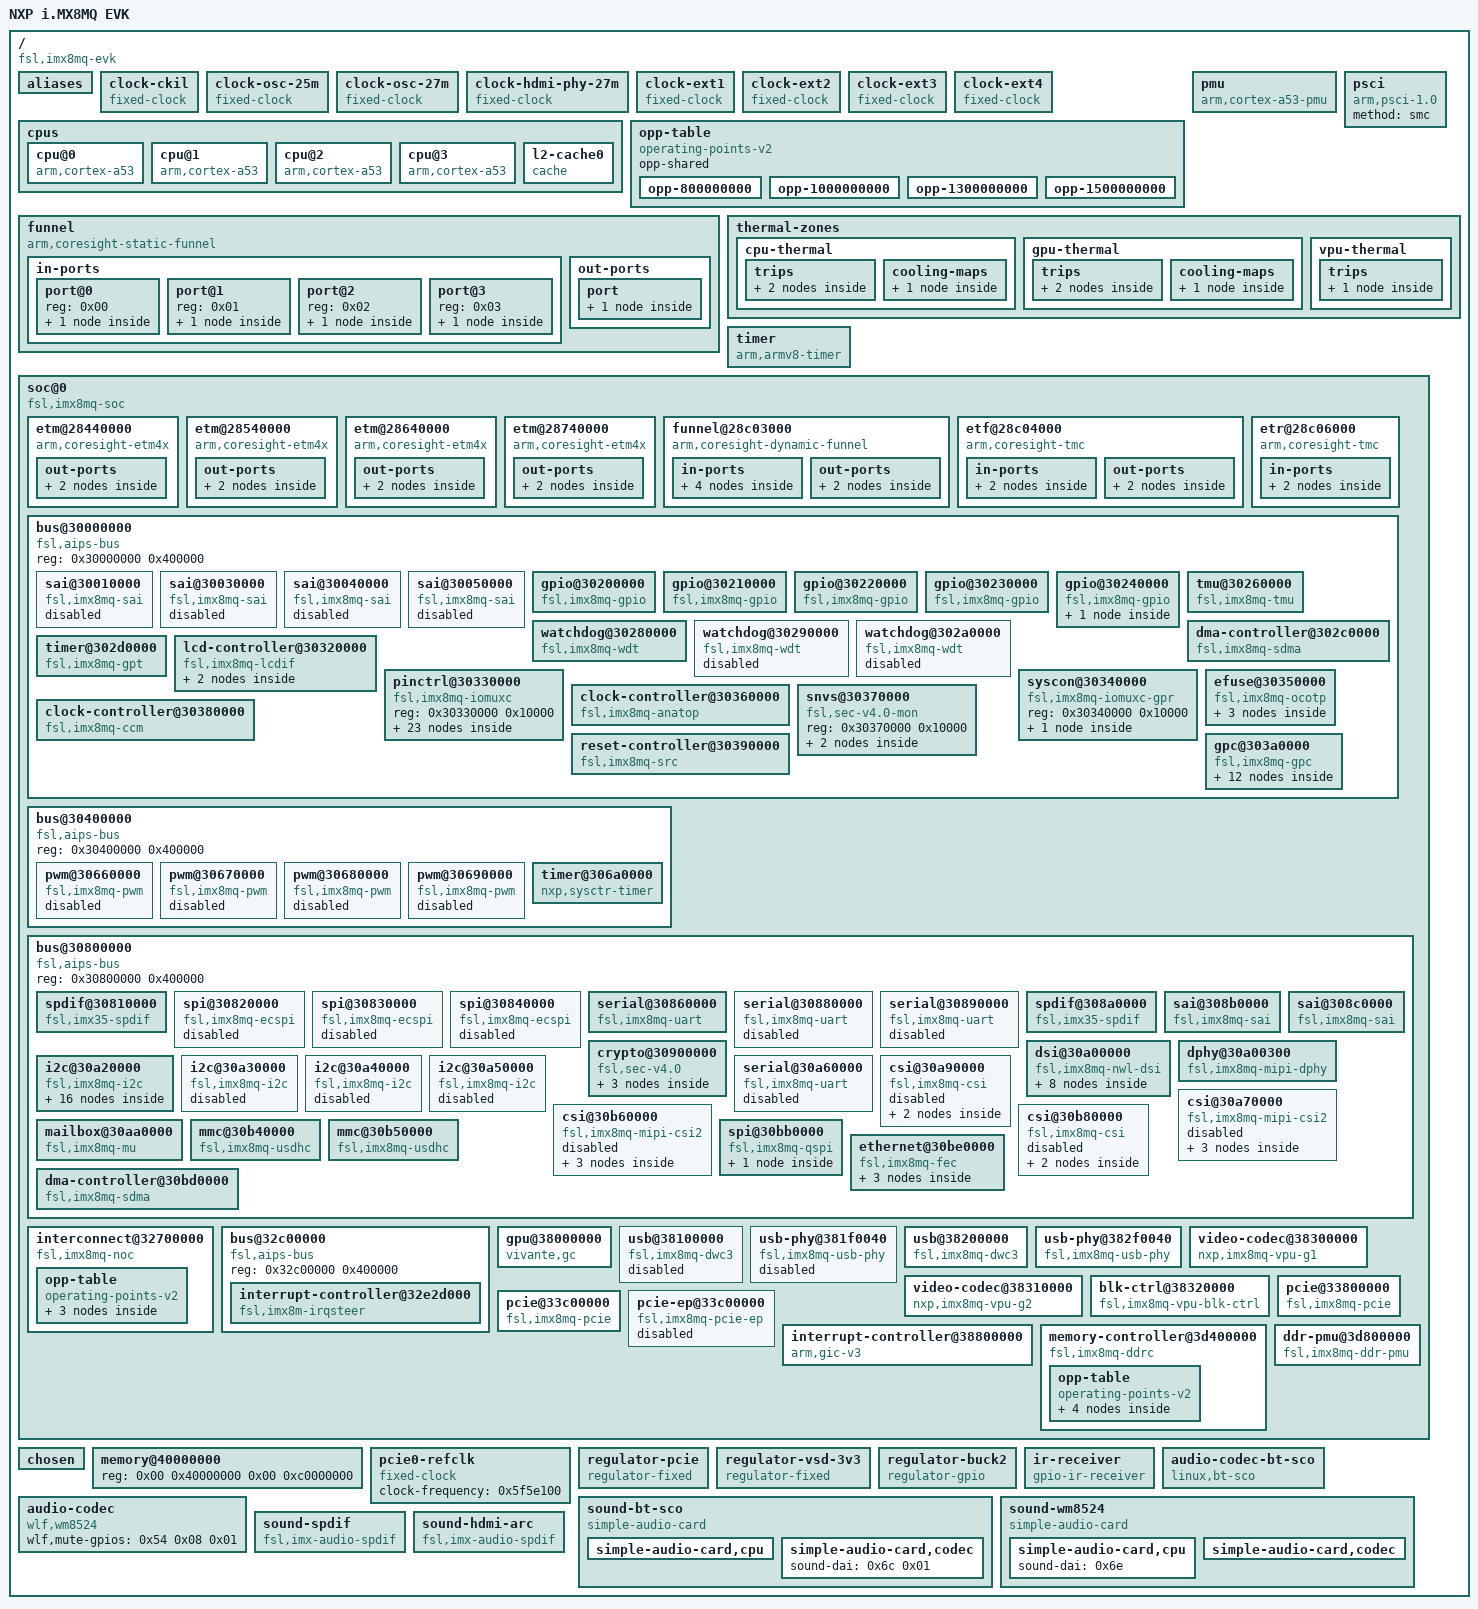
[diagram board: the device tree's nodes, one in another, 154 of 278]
/*
 * Copyright Linux Kernel Team
 *
 * SPDX-License-Identifier: GPL-2.0-only
 *
 * This file is derived from an intermediate build stage of the
 * Linux kernel. The licenses of all input files to this process
 * are compatible with GPL-2.0-only.
 */
/dts-v1/;

/ {
	interrupt-parent = <0x01>;
	#address-cells = <0x02>;
	#size-cells = <0x02>;
	model = "NXP i.MX8MQ EVK";
	compatible = "fsl,imx8mq-evk", "fsl,imx8mq";

	aliases {
		ethernet0 = "/soc@0/bus@30800000/ethernet@30be0000";
		gpio0 = "/soc@0/bus@30000000/gpio@30200000";
		gpio1 = "/soc@0/bus@30000000/gpio@30210000";
		gpio2 = "/soc@0/bus@30000000/gpio@30220000";
		gpio3 = "/soc@0/bus@30000000/gpio@30230000";
		gpio4 = "/soc@0/bus@30000000/gpio@30240000";
		i2c0 = "/soc@0/bus@30800000/i2c@30a20000";
		i2c1 = "/soc@0/bus@30800000/i2c@30a30000";
		i2c2 = "/soc@0/bus@30800000/i2c@30a40000";
		i2c3 = "/soc@0/bus@30800000/i2c@30a50000";
		mmc0 = "/soc@0/bus@30800000/mmc@30b40000";
		mmc1 = "/soc@0/bus@30800000/mmc@30b50000";
		serial0 = "/soc@0/bus@30800000/serial@30860000";
		serial1 = "/soc@0/bus@30800000/serial@30890000";
		serial2 = "/soc@0/bus@30800000/serial@30880000";
		serial3 = "/soc@0/bus@30800000/serial@30a60000";
		spi0 = "/soc@0/bus@30800000/spi@30820000";
		spi1 = "/soc@0/bus@30800000/spi@30830000";
		spi2 = "/soc@0/bus@30800000/spi@30840000";
	};

	clock-ckil {
		compatible = "fixed-clock";
		#clock-cells = <0x00>;
		clock-frequency = <0x8000>;
		clock-output-names = "ckil";
		phandle = <0x26>;
	};

	clock-osc-25m {
		compatible = "fixed-clock";
		#clock-cells = <0x00>;
		clock-frequency = <0x17d7840>;
		clock-output-names = "osc_25m";
		phandle = <0x27>;
	};

	clock-osc-27m {
		compatible = "fixed-clock";
		#clock-cells = <0x00>;
		clock-frequency = <0x19bfcc0>;
		clock-output-names = "osc_27m";
		phandle = <0x28>;
	};

	clock-hdmi-phy-27m {
		compatible = "fixed-clock";
		#clock-cells = <0x00>;
		clock-frequency = <0x19bfcc0>;
		clock-output-names = "hdmi_phy_27m";
	};

	clock-ext1 {
		compatible = "fixed-clock";
		#clock-cells = <0x00>;
		clock-frequency = <0x7ed6b40>;
		clock-output-names = "clk_ext1";
		phandle = <0x29>;
	};

	clock-ext2 {
		compatible = "fixed-clock";
		#clock-cells = <0x00>;
		clock-frequency = <0x7ed6b40>;
		clock-output-names = "clk_ext2";
		phandle = <0x2a>;
	};

	clock-ext3 {
		compatible = "fixed-clock";
		#clock-cells = <0x00>;
		clock-frequency = <0x7ed6b40>;
		clock-output-names = "clk_ext3";
		phandle = <0x2b>;
	};

	clock-ext4 {
		compatible = "fixed-clock";
		#clock-cells = <0x00>;
		clock-frequency = <0x7ed6b40>;
		clock-output-names = "clk_ext4";
		phandle = <0x2c>;
	};

	cpus {
		#address-cells = <0x01>;
		#size-cells = <0x00>;

		cpu@0 {
			device_type = "cpu";
			compatible = "arm,cortex-a53";
			reg = <0x00>;
			clock-latency = <0xee6c>;
			clocks = <0x02 0x102>;
			enable-method = "psci";
			i-cache-size = <0x8000>;
			i-cache-line-size = <0x40>;
			i-cache-sets = <0x100>;
			d-cache-size = <0x8000>;
			d-cache-line-size = <0x40>;
			d-cache-sets = <0x80>;
			next-level-cache = <0x03>;
			operating-points-v2 = <0x04>;
			#cooling-cells = <0x02>;
			nvmem-cells = <0x05>;
			nvmem-cell-names = "speed_grade";
			cpu-supply = <0x06>;
			phandle = <0x0f>;
		};

		cpu@1 {
			device_type = "cpu";
			compatible = "arm,cortex-a53";
			reg = <0x01>;
			clock-latency = <0xee6c>;
			clocks = <0x02 0x102>;
			enable-method = "psci";
			i-cache-size = <0x8000>;
			i-cache-line-size = <0x40>;
			i-cache-sets = <0x100>;
			d-cache-size = <0x8000>;
			d-cache-line-size = <0x40>;
			d-cache-sets = <0x80>;
			next-level-cache = <0x03>;
			operating-points-v2 = <0x04>;
			#cooling-cells = <0x02>;
			cpu-supply = <0x06>;
			phandle = <0x10>;
		};

		cpu@2 {
			device_type = "cpu";
			compatible = "arm,cortex-a53";
			reg = <0x02>;
			clock-latency = <0xee6c>;
			clocks = <0x02 0x102>;
			enable-method = "psci";
			i-cache-size = <0x8000>;
			i-cache-line-size = <0x40>;
			i-cache-sets = <0x100>;
			d-cache-size = <0x8000>;
			d-cache-line-size = <0x40>;
			d-cache-sets = <0x80>;
			next-level-cache = <0x03>;
			operating-points-v2 = <0x04>;
			#cooling-cells = <0x02>;
			cpu-supply = <0x06>;
			phandle = <0x11>;
		};

		cpu@3 {
			device_type = "cpu";
			compatible = "arm,cortex-a53";
			reg = <0x03>;
			clock-latency = <0xee6c>;
			clocks = <0x02 0x102>;
			enable-method = "psci";
			i-cache-size = <0x8000>;
			i-cache-line-size = <0x40>;
			i-cache-sets = <0x100>;
			d-cache-size = <0x8000>;
			d-cache-line-size = <0x40>;
			d-cache-sets = <0x80>;
			next-level-cache = <0x03>;
			operating-points-v2 = <0x04>;
			#cooling-cells = <0x02>;
			cpu-supply = <0x06>;
			phandle = <0x12>;
		};

		l2-cache0 {
			compatible = "cache";
			cache-level = <0x02>;
			cache-unified;
			cache-size = <0x100000>;
			cache-line-size = <0x40>;
			cache-sets = <0x400>;
			phandle = <0x03>;
		};
	};

	opp-table {
		compatible = "operating-points-v2";
		opp-shared;
		phandle = <0x04>;

		opp-800000000 {
			opp-hz = <0x00 0x2faf0800>;
			opp-microvolt = <0xdbba0>;
			opp-supported-hw = <0x0f 0x04>;
			clock-latency-ns = <0x249f0>;
			opp-suspend;
		};

		opp-1000000000 {
			opp-hz = <0x00 0x3b9aca00>;
			opp-microvolt = <0xdbba0>;
			opp-supported-hw = <0x0e 0x03>;
			clock-latency-ns = <0x249f0>;
			opp-suspend;
		};

		opp-1300000000 {
			opp-hz = <0x00 0x4d7c6d00>;
			opp-microvolt = <0xf4240>;
			opp-supported-hw = <0x0c 0x04>;
			clock-latency-ns = <0x249f0>;
			opp-suspend;
		};

		opp-1500000000 {
			opp-hz = <0x00 0x59682f00>;
			opp-microvolt = <0xf4240>;
			opp-supported-hw = <0x08 0x03>;
			clock-latency-ns = <0x249f0>;
			opp-suspend;
		};
	};

	funnel {
		compatible = "arm,coresight-static-funnel";

		in-ports {
			#address-cells = <0x01>;
			#size-cells = <0x00>;

			port@0 {
				reg = <0x00>;

				endpoint {
					remote-endpoint = <0x07>;
					phandle = <0x16>;
				};
			};

			port@1 {
				reg = <0x01>;

				endpoint {
					remote-endpoint = <0x08>;
					phandle = <0x17>;
				};
			};

			port@2 {
				reg = <0x02>;

				endpoint {
					remote-endpoint = <0x09>;
					phandle = <0x18>;
				};
			};

			port@3 {
				reg = <0x03>;

				endpoint {
					remote-endpoint = <0x0a>;
					phandle = <0x19>;
				};
			};
		};

		out-ports {

			port {

				endpoint {
					remote-endpoint = <0x0b>;
					phandle = <0x1a>;
				};
			};
		};
	};

	pmu {
		compatible = "arm,cortex-a53-pmu";
		interrupts = <0x01 0x07 0x04>;
		interrupt-parent = <0x0c>;
	};

	psci {
		compatible = "arm,psci-1.0";
		method = "smc";
	};

	thermal-zones {

		cpu-thermal {
			polling-delay-passive = <0xfa>;
			polling-delay = <0x7d0>;
			thermal-sensors = <0x0d 0x00>;

			trips {

				cpu-alert {
					temperature = <0x13880>;
					hysteresis = <0x7d0>;
					type = "passive";
					phandle = <0x0e>;
				};

				cpu-crit {
					temperature = <0x15f90>;
					hysteresis = <0x7d0>;
					type = "critical";
				};
			};

			cooling-maps {

				map0 {
					trip = <0x0e>;
					cooling-device = <0x0f 0xffffffff 0xffffffff 0x10 0xffffffff 0xffffffff 0x11 0xffffffff 0xffffffff 0x12 0xffffffff 0xffffffff>;
				};
			};
		};

		gpu-thermal {
			polling-delay-passive = <0xfa>;
			polling-delay = <0x7d0>;
			thermal-sensors = <0x0d 0x01>;

			trips {

				gpu-alert {
					temperature = <0x13880>;
					hysteresis = <0x7d0>;
					type = "passive";
					phandle = <0x13>;
				};

				gpu-crit {
					temperature = <0x15f90>;
					hysteresis = <0x7d0>;
					type = "critical";
				};
			};

			cooling-maps {

				map0 {
					trip = <0x13>;
					cooling-device = <0x14 0xffffffff 0xffffffff>;
				};
			};
		};

		vpu-thermal {
			polling-delay-passive = <0xfa>;
			polling-delay = <0x7d0>;
			thermal-sensors = <0x0d 0x02>;

			trips {

				vpu-crit {
					temperature = <0x15f90>;
					hysteresis = <0x7d0>;
					type = "critical";
				};
			};
		};
	};

	timer {
		compatible = "arm,armv8-timer";
		interrupts = <0x01 0x0d 0x08 0x01 0x0e 0x08 0x01 0x0b 0x08 0x01 0x0a 0x08>;
		interrupt-parent = <0x0c>;
		arm,no-tick-in-suspend;
	};

	soc@0 {
		compatible = "fsl,imx8mq-soc", "simple-bus";
		#address-cells = <0x01>;
		#size-cells = <0x01>;
		ranges = <0x00 0x00 0x00 0x3e000000>;
		dma-ranges = <0x40000000 0x00 0x40000000 0xc0000000>;
		nvmem-cells = <0x15>;
		nvmem-cell-names = "soc_unique_id";

		etm@28440000 {
			compatible = "arm,coresight-etm4x", "arm,primecell";
			reg = <0x28440000 0x1000>;
			cpu = <0x0f>;
			clocks = <0x02 0x67>;
			clock-names = "apb_pclk";

			out-ports {

				port {

					endpoint {
						remote-endpoint = <0x16>;
						phandle = <0x07>;
					};
				};
			};
		};

		etm@28540000 {
			compatible = "arm,coresight-etm4x", "arm,primecell";
			reg = <0x28540000 0x1000>;
			cpu = <0x10>;
			clocks = <0x02 0x67>;
			clock-names = "apb_pclk";

			out-ports {

				port {

					endpoint {
						remote-endpoint = <0x17>;
						phandle = <0x08>;
					};
				};
			};
		};

		etm@28640000 {
			compatible = "arm,coresight-etm4x", "arm,primecell";
			reg = <0x28640000 0x1000>;
			cpu = <0x11>;
			clocks = <0x02 0x67>;
			clock-names = "apb_pclk";

			out-ports {

				port {

					endpoint {
						remote-endpoint = <0x18>;
						phandle = <0x09>;
					};
				};
			};
		};

		etm@28740000 {
			compatible = "arm,coresight-etm4x", "arm,primecell";
			reg = <0x28740000 0x1000>;
			cpu = <0x12>;
			clocks = <0x02 0x67>;
			clock-names = "apb_pclk";

			out-ports {

				port {

					endpoint {
						remote-endpoint = <0x19>;
						phandle = <0x0a>;
					};
				};
			};
		};

		funnel@28c03000 {
			compatible = "arm,coresight-dynamic-funnel", "arm,primecell";
			reg = <0x28c03000 0x1000>;
			clocks = <0x02 0x67>;
			clock-names = "apb_pclk";

			in-ports {
				#address-cells = <0x01>;
				#size-cells = <0x00>;

				port@0 {
					reg = <0x00>;

					endpoint {
						remote-endpoint = <0x1a>;
						phandle = <0x0b>;
					};
				};

				port@1 {
					reg = <0x01>;

					endpoint {
					};
				};
			};

			out-ports {

				port {

					endpoint {
						remote-endpoint = <0x1b>;
						phandle = <0x1c>;
					};
				};
			};
		};

		etf@28c04000 {
			compatible = "arm,coresight-tmc", "arm,primecell";
			reg = <0x28c04000 0x1000>;
			clocks = <0x02 0x67>;
			clock-names = "apb_pclk";

			in-ports {

				port {

					endpoint {
						remote-endpoint = <0x1c>;
						phandle = <0x1b>;
					};
				};
			};

			out-ports {

				port {

					endpoint {
						remote-endpoint = <0x1d>;
						phandle = <0x1e>;
					};
				};
			};
		};

		etr@28c06000 {
			compatible = "arm,coresight-tmc", "arm,primecell";
			reg = <0x28c06000 0x1000>;
			clocks = <0x02 0x67>;
			clock-names = "apb_pclk";

			in-ports {

				port {

					endpoint {
						remote-endpoint = <0x1e>;
						phandle = <0x1d>;
					};
				};
			};
		};

		bus@30000000 {
			compatible = "fsl,aips-bus", "simple-bus";
			reg = <0x30000000 0x400000>;
			#address-cells = <0x01>;
			#size-cells = <0x01>;
			ranges = <0x30000000 0x30000000 0x400000>;

			sai@30010000 {
				#sound-dai-cells = <0x00>;
				compatible = "fsl,imx8mq-sai";
				reg = <0x30010000 0x10000>;
				interrupts = <0x00 0x5f 0x04>;
				clocks = <0x02 0xee 0x02 0xc4 0x02 0x00 0x02 0x00>;
				clock-names = "bus", "mclk1", "mclk2", "mclk3";
				dmas = <0x1f 0x08 0x18 0x00 0x20 0x09 0x18 0x00>;
				dma-names = "rx", "tx";
				status = "disabled";
			};

			sai@30030000 {
				#sound-dai-cells = <0x00>;
				compatible = "fsl,imx8mq-sai";
				reg = <0x30030000 0x10000>;
				interrupts = <0x00 0x5a 0x04>;
				clocks = <0x02 0xf3 0x02 0xc9 0x02 0x00 0x02 0x00>;
				clock-names = "bus", "mclk1", "mclk2", "mclk3";
				dmas = <0x1f 0x04 0x18 0x00 0x1f 0x05 0x18 0x00>;
				dma-names = "rx", "tx";
				status = "disabled";
			};

			sai@30040000 {
				#sound-dai-cells = <0x00>;
				compatible = "fsl,imx8mq-sai";
				reg = <0x30040000 0x10000>;
				interrupts = <0x00 0x5a 0x04>;
				clocks = <0x02 0xf2 0x02 0xc8 0x02 0x00 0x02 0x00>;
				clock-names = "bus", "mclk1", "mclk2", "mclk3";
				dmas = <0x1f 0x02 0x18 0x00 0x1f 0x03 0x18 0x00>;
				dma-names = "rx", "tx";
				status = "disabled";
			};

			sai@30050000 {
				#sound-dai-cells = <0x00>;
				compatible = "fsl,imx8mq-sai";
				reg = <0x30050000 0x10000>;
				interrupts = <0x00 0x64 0x04>;
				clocks = <0x02 0xf1 0x02 0xc7 0x02 0x00 0x02 0x00>;
				clock-names = "bus", "mclk1", "mclk2", "mclk3";
				dmas = <0x1f 0x00 0x18 0x00 0x1f 0x01 0x18 0x00>;
				dma-names = "rx", "tx";
				status = "disabled";
			};

			gpio@30200000 {
				compatible = "fsl,imx8mq-gpio", "fsl,imx35-gpio";
				reg = <0x30200000 0x10000>;
				interrupts = <0x00 0x40 0x04 0x00 0x41 0x04>;
				clocks = <0x02 0x103>;
				gpio-controller;
				#gpio-cells = <0x02>;
				interrupt-controller;
				#interrupt-cells = <0x02>;
				gpio-ranges = <0x21 0x00 0x0a 0x1e>;
				phandle = <0x54>;
			};

			gpio@30210000 {
				compatible = "fsl,imx8mq-gpio", "fsl,imx35-gpio";
				reg = <0x30210000 0x10000>;
				interrupts = <0x00 0x42 0x04 0x00 0x43 0x04>;
				clocks = <0x02 0x104>;
				gpio-controller;
				#gpio-cells = <0x02>;
				interrupt-controller;
				#interrupt-cells = <0x02>;
				gpio-ranges = <0x21 0x00 0x28 0x15>;
				phandle = <0x4e>;
			};

			gpio@30220000 {
				compatible = "fsl,imx8mq-gpio", "fsl,imx35-gpio";
				reg = <0x30220000 0x10000>;
				interrupts = <0x00 0x44 0x04 0x00 0x45 0x04>;
				clocks = <0x02 0x105>;
				gpio-controller;
				#gpio-cells = <0x02>;
				interrupt-controller;
				#interrupt-cells = <0x02>;
				gpio-ranges = <0x21 0x00 0x3d 0x1a>;
			};

			gpio@30230000 {
				compatible = "fsl,imx8mq-gpio", "fsl,imx35-gpio";
				reg = <0x30230000 0x10000>;
				interrupts = <0x00 0x46 0x04 0x00 0x47 0x04>;
				clocks = <0x02 0x106>;
				gpio-controller;
				#gpio-cells = <0x02>;
				interrupt-controller;
				#interrupt-cells = <0x02>;
				gpio-ranges = <0x21 0x00 0x57 0x20>;
			};

			gpio@30240000 {
				compatible = "fsl,imx8mq-gpio", "fsl,imx35-gpio";
				reg = <0x30240000 0x10000>;
				interrupts = <0x00 0x48 0x04 0x00 0x49 0x04>;
				clocks = <0x02 0x107>;
				gpio-controller;
				#gpio-cells = <0x02>;
				interrupt-controller;
				#interrupt-cells = <0x02>;
				gpio-ranges = <0x21 0x00 0x77 0x1e>;
				pinctrl-names = "default";
				pinctrl-0 = <0x22>;
				phandle = <0x3b>;

				wl-reg-on-hog {
					gpio-hog;
					gpios = <0x1d 0x00>;
					output-high;
				};
			};

			tmu@30260000 {
				compatible = "fsl,imx8mq-tmu";
				reg = <0x30260000 0x10000>;
				interrupts = <0x00 0x31 0x04>;
				clocks = <0x02 0xf6>;
				little-endian;
				fsl,tmu-range = <0xb0000 0xa0026 0x80048 0x70061>;
				fsl,tmu-calibration = <0x00 0x23 0x01 0x29 0x02 0x2f 0x03 0x35 0x04 0x3d 0x05 0x43 0x06 0x4b 0x07 0x51 0x08 0x57 0x09 0x5f 0x0a 0x67 0x0b 0x6f 0x10000 0x1b 0x10001 0x23 0x10002 0x2b 0x10003 0x33 0x10004 0x3b 0x10005 0x43 0x10006 0x4b 0x10007 0x55 0x10008 0x5d 0x10009 0x67 0x1000a 0x70 0x20000 0x17 0x20001 0x23 0x20002 0x2d 0x20003 0x37 0x20004 0x41 0x20005 0x4b 0x20006 0x57 0x20007 0x63 0x20008 0x6f 0x30000 0x15 0x30001 0x21 0x30002 0x2d 0x30003 0x39 0x30004 0x45 0x30005 0x53 0x30006 0x5f 0x30007 0x71>;
				#thermal-sensor-cells = <0x01>;
				phandle = <0x0d>;
			};

			watchdog@30280000 {
				compatible = "fsl,imx8mq-wdt", "fsl,imx21-wdt";
				reg = <0x30280000 0x10000>;
				interrupts = <0x00 0x4e 0x04>;
				clocks = <0x02 0xd4>;
				status = "okay";
				pinctrl-names = "default";
				pinctrl-0 = <0x23>;
				fsl,ext-reset-output;
			};

			watchdog@30290000 {
				compatible = "fsl,imx8mq-wdt", "fsl,imx21-wdt";
				reg = <0x30290000 0x10000>;
				interrupts = <0x00 0x4f 0x04>;
				clocks = <0x02 0xd5>;
				status = "disabled";
			};

			watchdog@302a0000 {
				compatible = "fsl,imx8mq-wdt", "fsl,imx21-wdt";
				reg = <0x302a0000 0x10000>;
				interrupts = <0x00 0x0a 0x04>;
				clocks = <0x02 0xd6>;
				status = "disabled";
			};

			dma-controller@302c0000 {
				compatible = "fsl,imx8mq-sdma", "fsl,imx7d-sdma";
				reg = <0x302c0000 0x10000>;
				interrupts = <0x00 0x67 0x04>;
				clocks = <0x02 0xe4 0x02 0xe4>;
				clock-names = "ipg", "ahb";
				#dma-cells = <0x03>;
				fsl,sdma-ram-script-name = "imx/sdma/sdma-imx7d.bin";
				phandle = <0x1f>;
			};

			timer@302d0000 {
				compatible = "fsl,imx8mq-gpt";
				reg = <0x302d0000 0x10000>;
				interrupts = <0x00 0x37 0x04>;
			};

			lcd-controller@30320000 {
				compatible = "fsl,imx8mq-lcdif", "fsl,imx6sx-lcdif";
				reg = <0x30320000 0x10000>;
				interrupts = <0x00 0x05 0x04>;
				clocks = <0x02 0x80 0x02 0xf8 0x02 0xf7>;
				clock-names = "pix", "axi", "disp_axi";
				assigned-clocks = <0x02 0x21 0x02 0x24 0x02 0x80 0x02 0x23>;
				assigned-clock-parents = <0x02 0x02 0x02 0x23 0x02 0x25>;
				assigned-clock-rates = <0x00 0x00 0x00 0x2367b880>;
				status = "okay";

				port {

					endpoint {
						remote-endpoint = <0x24>;
						phandle = <0x38>;
					};
				};
			};

			pinctrl@30330000 {
				compatible = "fsl,imx8mq-iomuxc";
				reg = <0x30330000 0x10000>;
				phandle = <0x21>;

				vddarmgrp {
					fsl,pins = <0x5c 0x2c4 0x00 0x00 0x00 0x19>;
					phandle = <0x68>;
				};

				fec1grp {
					fsl,pins = <0x68 0x2d0 0x00 0x00 0x00 0x03 0x6c 0x2d4 0x4c0 0x00 0x01 0x23 0x70 0x2d8 0x00 0x00 0x00 0x1f 0x74 0x2dc 0x00 0x00 0x00 0x1f 0x78 0x2e0 0x00 0x00 0x00 0x1f 0x7c 0x2e4 0x00 0x00 0x00 0x1f 0x9c 0x304 0x00 0x00 0x00 0x91 0x98 0x300 0x00 0x00 0x00 0x91 0x94 0x2fc 0x00 0x00 0x00 0x91 0x90 0x2f8 0x00 0x00 0x00 0x91 0x84 0x2ec 0x00 0x00 0x00 0x1f 0x8c 0x2f4 0x00 0x00 0x00 0x91 0x88 0x2f0 0x00 0x00 0x00 0x91 0x80 0x2e8 0x00 0x00 0x00 0x1f 0x4c 0x2b4 0x00 0x00 0x00 0x19>;
					phandle = <0x52>;
				};

				i2c1grp {
					fsl,pins = <0x214 0x47c 0x00 0x00 0x00 0x4000007f 0x218 0x480 0x00 0x00 0x00 0x4000007f>;
					phandle = <0x3d>;
				};

				irgrp {
					fsl,pins = <0x58 0x2c0 0x00 0x00 0x00 0x4f>;
					phandle = <0x69>;
				};

				mipidsigrp {
					fsl,pins = <0x1f4 0x45c 0x00 0x05 0x00 0x16>;
					phandle = <0x3a>;
				};

				pcie0grp {
					fsl,pins = <0x22c 0x494 0x524 0x02 0x00 0x76 0x24c 0x4b4 0x00 0x05 0x00 0x16>;
					phandle = <0x61>;
				};

				pcie1grp {
					fsl,pins = <0x230 0x498 0x528 0x02 0x00 0x76 0x20c 0x474 0x00 0x05 0x00 0x16>;
					phandle = <0x63>;
				};

				pcie1reggrp {
					fsl,pins = <0x204 0x46c 0x00 0x05 0x00 0x16>;
					phandle = <0x66>;
				};

				qspigrp {
					fsl,pins = <0xf4 0x35c 0x00 0x01 0x00 0x82 0xf8 0x360 0x00 0x01 0x00 0x82 0x10c 0x374 0x00 0x01 0x00 0x82 0x110 0x378 0x00 0x01 0x00 0x82 0x114 0x37c 0x00 0x01 0x00 0x82 0x118 0x380 0x00 0x01 0x00 0x82>;
					phandle = <0x50>;
				};

				regusdhc2gpiogrp {
					fsl,pins = <0xec 0x354 0x00 0x05 0x00 0x41>;
					phandle = <0x67>;
				};

				sai2grp {
					fsl,pins = <0x1bc 0x424 0x00 0x00 0x00 0xd6 0x1c0 0x428 0x00 0x00 0x00 0xd6 0x1c8 0x430 0x00 0x00 0x00 0xd6 0x1c4 0x42c 0x00 0x00 0x00 0xd6 0x48 0x2b0 0x00 0x00 0x00 0xd6>;
					phandle = <0x32>;
				};

				sai3grp {
					fsl,pins = <0x1d8 0x440 0x00 0x00 0x00 0xd6 0x1dc 0x444 0x00 0x00 0x00 0xd6 0x1e0 0x448 0x00 0x00 0x00 0xd6 0x1d4 0x43c 0x00 0x00 0x00 0xd6>;
					phandle = <0x33>;
				};

				spdif1grp {
					fsl,pins = <0x1e8 0x450 0x00 0x00 0x00 0xd6 0x1ec 0x454 0x00 0x00 0x00 0xd6>;
					phandle = <0x30>;
				};

				uart1grp {
					fsl,pins = <0x234 0x49c 0x4f4 0x00 0x00 0x49 0x238 0x4a0 0x00 0x00 0x00 0x49>;
					phandle = <0x31>;
				};

				usdhc1grp {
					fsl,pins = <0xa0 0x308 0x00 0x00 0x00 0x83 0xa4 0x30c 0x00 0x00 0x00 0xc3 0xa8 0x310 0x00 0x00 0x00 0xc3 0xac 0x314 0x00 0x00 0x00 0xc3 0xb0 0x318 0x00 0x00 0x00 0xc3 0xb4 0x31c 0x00 0x00 0x00 0xc3 0xb8 0x320 0x00 0x00 0x00 0xc3 0xbc 0x324 0x00 0x00 0x00 0xc3 0xc0 0x328 0x00 0x00 0x00 0xc3 0xc4 0x32c 0x00 0x00 0x00 0xc3 0xcc 0x334 0x00 0x00 0x00 0x83 0xc8 0x330 0x00 0x00 0x00 0xc1>;
					phandle = <0x46>;
				};

				usdhc1-100grp {
					fsl,pins = <0xa0 0x308 0x00 0x00 0x00 0x8d 0xa4 0x30c 0x00 0x00 0x00 0xcd 0xa8 0x310 0x00 0x00 0x00 0xcd 0xac 0x314 0x00 0x00 0x00 0xcd 0xb0 0x318 0x00 0x00 0x00 0xcd 0xb4 0x31c 0x00 0x00 0x00 0xcd 0xb8 0x320 0x00 0x00 0x00 0xcd 0xbc 0x324 0x00 0x00 0x00 0xcd 0xc0 0x328 0x00 0x00 0x00 0xcd 0xc4 0x32c 0x00 0x00 0x00 0xcd 0xcc 0x334 0x00 0x00 0x00 0x8d 0xc8 0x330 0x00 0x00 0x00 0xc1>;
					phandle = <0x47>;
				};

				usdhc1-200grp {
					fsl,pins = <0xa0 0x308 0x00 0x00 0x00 0x9f 0xa4 0x30c 0x00 0x00 0x00 0xdf 0xa8 0x310 0x00 0x00 0x00 0xdf 0xac 0x314 0x00 0x00 0x00 0xdf 0xb0 0x318 0x00 0x00 0x00 0xdf 0xb4 0x31c 0x00 0x00 0x00 0xdf 0xb8 0x320 0x00 0x00 0x00 0xdf 0xbc 0x324 0x00 0x00 0x00 0xdf 0xc0 0x328 0x00 0x00 0x00 0xdf 0xc4 0x32c 0x00 0x00 0x00 0xdf 0xcc 0x334 0x00 0x00 0x00 0x9f 0xc8 0x330 0x00 0x00 0x00 0xc1>;
					phandle = <0x48>;
				};

				usdhc2gpiogrp {
					fsl,pins = <0xd0 0x338 0x00 0x05 0x00 0x41>;
					phandle = <0x4b>;
				};

				usdhc2grp {
					fsl,pins = <0xd4 0x33c 0x00 0x00 0x00 0x83 0xd8 0x340 0x00 0x00 0x00 0xc3 0xdc 0x344 0x00 0x00 0x00 0xc3 0xe0 0x348 0x00 0x00 0x00 0xc3 0xe4 0x34c 0x00 0x00 0x00 0xc3 0xe8 0x350 0x00 0x00 0x00 0xc3 0x38 0x2a0 0x00 0x01 0x00 0xc1>;
					phandle = <0x4a>;
				};

				usdhc2-100grp {
					fsl,pins = <0xd4 0x33c 0x00 0x00 0x00 0x85 0xd8 0x340 0x00 0x00 0x00 0xc5 0xdc 0x344 0x00 0x00 0x00 0xc5 0xe0 0x348 0x00 0x00 0x00 0xc5 0xe4 0x34c 0x00 0x00 0x00 0xc5 0xe8 0x350 0x00 0x00 0x00 0xc5 0x38 0x2a0 0x00 0x01 0x00 0xc1>;
					phandle = <0x4c>;
				};

				usdhc2-200grp {
					fsl,pins = <0xd4 0x33c 0x00 0x00 0x00 0x87 0xd8 0x340 0x00 0x00 0x00 0xc7 0xdc 0x344 0x00 0x00 0x00 0xc7 0xe0 0x348 0x00 0x00 0x00 0xc7 0xe4 0x34c 0x00 0x00 0x00 0xc7 0xe8 0x350 0x00 0x00 0x00 0xc7 0x38 0x2a0 0x00 0x01 0x00 0xc1>;
					phandle = <0x4d>;
				};

				wdog1grp {
					fsl,pins = <0x30 0x298 0x00 0x01 0x00 0xc6>;
					phandle = <0x23>;
				};

				wifiresetgrp {
					fsl,pins = <0x250 0x4b8 0x00 0x05 0x00 0x16>;
					phandle = <0x22>;
				};
			};

			syscon@30340000 {
				compatible = "fsl,imx8mq-iomuxc-gpr", "syscon", "simple-mfd";
				reg = <0x30340000 0x10000>;
				phandle = <0x3f>;

				mux-controller {
					compatible = "mmio-mux";
					#mux-control-cells = <0x01>;
					mux-reg-masks = <0x34 0x04>;
					phandle = <0x34>;
				};
			};

			efuse@30350000 {
				compatible = "fsl,imx8mq-ocotp", "syscon";
				reg = <0x30350000 0x10000>;
				clocks = <0x02 0xfa>;
				#address-cells = <0x01>;
				#size-cells = <0x01>;

				soc-uid@4 {
					reg = <0x04 0x08>;
					phandle = <0x15>;
				};

				speed-grade@10 {
					reg = <0x10 0x04>;
					phandle = <0x05>;
				};

				mac-address@90 {
					reg = <0x90 0x06>;
					phandle = <0x51>;
				};
			};

			clock-controller@30360000 {
				compatible = "fsl,imx8mq-anatop";
				reg = <0x30360000 0x10000>;
				interrupts = <0x00 0x31 0x04>;
				#clock-cells = <0x01>;
			};

			snvs@30370000 {
				compatible = "fsl,sec-v4.0-mon", "syscon", "simple-mfd";
				reg = <0x30370000 0x10000>;
				phandle = <0x25>;

				snvs-rtc-lp {
					compatible = "fsl,sec-v4.0-mon-rtc-lp";
					regmap = <0x25>;
					offset = <0x34>;
					interrupts = <0x00 0x13 0x04 0x00 0x14 0x04>;
					clocks = <0x02 0x108>;
					clock-names = "snvs-rtc";
				};

				snvs-powerkey {
					compatible = "fsl,sec-v4.0-pwrkey";
					regmap = <0x25>;
					interrupts = <0x00 0x04 0x04>;
					clocks = <0x02 0x108>;
					clock-names = "snvs-pwrkey";
					linux,keycode = <0x74>;
					wakeup-source;
					status = "okay";
				};
			};

			clock-controller@30380000 {
				compatible = "fsl,imx8mq-ccm";
				reg = <0x30380000 0x10000>;
				interrupts = <0x00 0x55 0x04 0x00 0x56 0x04>;
				#clock-cells = <0x01>;
				clocks = <0x26 0x27 0x28 0x29 0x2a 0x2b 0x2c>;
				clock-names = "ckil", "osc_25m", "osc_27m", "clk_ext1", "clk_ext2", "clk_ext3", "clk_ext4";
				assigned-clocks = <0x02 0x58 0x02 0x121 0x02 0x71 0x02 0x75 0x02 0x1a 0x02 0x1f 0x02 0x19 0x02 0x1e>;
				assigned-clock-rates = <0x00 0x00 0x2faf0800 0x00 0x00 0x00 0x2ee00000 0x2b110000>;
				assigned-clock-parents = <0x02 0x4e 0x02 0x0c 0x00 0x02 0x56 0x02 0x19 0x02 0x1e>;
				phandle = <0x02>;
			};

			reset-controller@30390000 {
				compatible = "fsl,imx8mq-src", "syscon";
				reg = <0x30390000 0x10000>;
				interrupts = <0x00 0x59 0x04>;
				#reset-cells = <0x01>;
				phandle = <0x37>;
			};

			gpc@303a0000 {
				compatible = "fsl,imx8mq-gpc";
				reg = <0x303a0000 0x10000>;
				interrupts = <0x00 0x57 0x04>;
				interrupt-parent = <0x0c>;
				interrupt-controller;
				#interrupt-cells = <0x03>;
				phandle = <0x01>;

				pgc {
					#address-cells = <0x01>;
					#size-cells = <0x00>;

					power-domain@0 {
						#power-domain-cells = <0x00>;
						reg = <0x00>;
						phandle = <0x35>;
					};

					power-domain@1 {
						#power-domain-cells = <0x00>;
						reg = <0x01>;
						power-domains = <0x2d>;
						phandle = <0x60>;
					};

					power-domain@2 {
						#power-domain-cells = <0x00>;
						reg = <0x02>;
						phandle = <0x5a>;
					};

					power-domain@3 {
						#power-domain-cells = <0x00>;
						reg = <0x03>;
						phandle = <0x5c>;
					};

					power-domain@4 {
						#power-domain-cells = <0x00>;
						reg = <0x04>;
					};

					power-domain@5 {
						#power-domain-cells = <0x00>;
						reg = <0x05>;
						clocks = <0x02 0xd7 0x02 0x66 0x02 0x6f 0x02 0x70>;
						power-supply = <0x2e>;
						phandle = <0x58>;
					};

					power-domain@6 {
						#power-domain-cells = <0x00>;
						reg = <0x06>;
						clocks = <0x02 0xdf 0x02 0xe5 0x02 0xe6>;
						assigned-clocks = <0x02 0x78 0x02 0x79 0x02 0x6a 0x02 0x15>;
						assigned-clock-parents = <0x02 0x16 0x02 0x16 0x02 0x4e 0x02 0x14>;
						assigned-clock-rates = <0x23c34600 0x11e1a300 0x2faf0800 0x00>;
						power-supply = <0x2f>;
						phandle = <0x5e>;
					};

					power-domain@7 {
						#power-domain-cells = <0x00>;
						reg = <0x07>;
					};

					power-domain@8 {
						#power-domain-cells = <0x00>;
						reg = <0x08>;
						phandle = <0x3e>;
					};

					power-domain@9 {
						#power-domain-cells = <0x00>;
						reg = <0x09>;
						phandle = <0x43>;
					};

					power-domain@a {
						#power-domain-cells = <0x00>;
						reg = <0x0a>;
						phandle = <0x2d>;
					};
				};
			};
		};

		bus@30400000 {
			compatible = "fsl,aips-bus", "simple-bus";
			reg = <0x30400000 0x400000>;
			#address-cells = <0x01>;
			#size-cells = <0x01>;
			ranges = <0x30400000 0x30400000 0x400000>;

			pwm@30660000 {
				compatible = "fsl,imx8mq-pwm", "fsl,imx27-pwm";
				reg = <0x30660000 0x10000>;
				interrupts = <0x00 0x51 0x04>;
				clocks = <0x02 0xbf 0x02 0xbf>;
				clock-names = "ipg", "per";
				#pwm-cells = <0x03>;
				status = "disabled";
			};

			pwm@30670000 {
				compatible = "fsl,imx8mq-pwm", "fsl,imx27-pwm";
				reg = <0x30670000 0x10000>;
				interrupts = <0x00 0x52 0x04>;
				clocks = <0x02 0xc0 0x02 0xc0>;
				clock-names = "ipg", "per";
				#pwm-cells = <0x03>;
				status = "disabled";
			};

			pwm@30680000 {
				compatible = "fsl,imx8mq-pwm", "fsl,imx27-pwm";
				reg = <0x30680000 0x10000>;
				interrupts = <0x00 0x53 0x04>;
				clocks = <0x02 0xc1 0x02 0xc1>;
				clock-names = "ipg", "per";
				#pwm-cells = <0x03>;
				status = "disabled";
			};

			pwm@30690000 {
				compatible = "fsl,imx8mq-pwm", "fsl,imx27-pwm";
				reg = <0x30690000 0x10000>;
				interrupts = <0x00 0x54 0x04>;
				clocks = <0x02 0xc2 0x02 0xc2>;
				clock-names = "ipg", "per";
				#pwm-cells = <0x03>;
				status = "disabled";
			};

			timer@306a0000 {
				compatible = "nxp,sysctr-timer";
				reg = <0x306a0000 0x20000>;
				interrupts = <0x00 0x2f 0x04>;
				clocks = <0x27>;
				clock-names = "per";
			};
		};

		bus@30800000 {
			compatible = "fsl,aips-bus", "simple-bus";
			reg = <0x30800000 0x400000>;
			#address-cells = <0x01>;
			#size-cells = <0x01>;
			ranges = <0x30800000 0x30800000 0x400000 0x8000000 0x8000000 0x10000000>;

			spdif@30810000 {
				compatible = "fsl,imx35-spdif";
				reg = <0x30810000 0x10000>;
				interrupts = <0x00 0x06 0x04>;
				clocks = <0x02 0xec 0x02 0x02 0x02 0x87 0x02 0x00 0x02 0x00 0x02 0x00 0x02 0xec 0x02 0x00 0x02 0x00 0x02 0x00>;
				clock-names = "core", "rxtx0", "rxtx1", "rxtx2", "rxtx3", "rxtx4", "rxtx5", "rxtx6", "rxtx7", "spba";
				dmas = <0x20 0x08 0x12 0x00 0x20 0x09 0x12 0x00>;
				dma-names = "rx", "tx";
				status = "okay";
				pinctrl-names = "default";
				pinctrl-0 = <0x30>;
				assigned-clocks = <0x02 0x87>;
				assigned-clock-parents = <0x02 0x1b>;
				assigned-clock-rates = <0x1770000>;
				phandle = <0x70>;
			};

			spi@30820000 {
				#address-cells = <0x01>;
				#size-cells = <0x00>;
				compatible = "fsl,imx8mq-ecspi", "fsl,imx51-ecspi";
				reg = <0x30820000 0x10000>;
				interrupts = <0x00 0x1f 0x04>;
				clocks = <0x02 0xb3 0x02 0xb3>;
				clock-names = "ipg", "per";
				dmas = <0x20 0x00 0x07 0x01 0x20 0x01 0x07 0x02>;
				dma-names = "rx", "tx";
				status = "disabled";
			};

			spi@30830000 {
				#address-cells = <0x01>;
				#size-cells = <0x00>;
				compatible = "fsl,imx8mq-ecspi", "fsl,imx51-ecspi";
				reg = <0x30830000 0x10000>;
				interrupts = <0x00 0x20 0x04>;
				clocks = <0x02 0xb4 0x02 0xb4>;
				clock-names = "ipg", "per";
				dmas = <0x20 0x02 0x07 0x01 0x20 0x03 0x07 0x02>;
				dma-names = "rx", "tx";
				status = "disabled";
			};

			spi@30840000 {
				#address-cells = <0x01>;
				#size-cells = <0x00>;
				compatible = "fsl,imx8mq-ecspi", "fsl,imx51-ecspi";
				reg = <0x30840000 0x10000>;
				interrupts = <0x00 0x21 0x04>;
				clocks = <0x02 0xb5 0x02 0xb5>;
				clock-names = "ipg", "per";
				dmas = <0x20 0x04 0x07 0x01 0x20 0x05 0x07 0x02>;
				dma-names = "rx", "tx";
				status = "disabled";
			};

			serial@30860000 {
				compatible = "fsl,imx8mq-uart", "fsl,imx6q-uart";
				reg = <0x30860000 0x10000>;
				interrupts = <0x00 0x1a 0x04>;
				clocks = <0x02 0xca 0x02 0xca>;
				clock-names = "ipg", "per";
				dmas = <0x20 0x16 0x04 0x00 0x20 0x17 0x04 0x00>;
				dma-names = "rx", "tx";
				status = "okay";
				pinctrl-names = "default";
				pinctrl-0 = <0x31>;
			};

			serial@30880000 {
				compatible = "fsl,imx8mq-uart", "fsl,imx6q-uart";
				reg = <0x30880000 0x10000>;
				interrupts = <0x00 0x1c 0x04>;
				clocks = <0x02 0xcc 0x02 0xcc>;
				clock-names = "ipg", "per";
				dmas = <0x20 0x1a 0x04 0x00 0x20 0x1b 0x04 0x00>;
				dma-names = "rx", "tx";
				status = "disabled";
			};

			serial@30890000 {
				compatible = "fsl,imx8mq-uart", "fsl,imx6q-uart";
				reg = <0x30890000 0x10000>;
				interrupts = <0x00 0x1b 0x04>;
				clocks = <0x02 0xcb 0x02 0xcb>;
				clock-names = "ipg", "per";
				dmas = <0x20 0x18 0x04 0x00 0x20 0x19 0x04 0x00>;
				dma-names = "rx", "tx";
				status = "disabled";
			};

			spdif@308a0000 {
				compatible = "fsl,imx35-spdif";
				reg = <0x308a0000 0x10000>;
				interrupts = <0x00 0x0d 0x04>;
				clocks = <0x02 0xec 0x02 0x02 0x02 0x88 0x02 0x00 0x02 0x00 0x02 0x00 0x02 0xec 0x02 0x00 0x02 0x00 0x02 0x00>;
				clock-names = "core", "rxtx0", "rxtx1", "rxtx2", "rxtx3", "rxtx4", "rxtx5", "rxtx6", "rxtx7", "spba";
				dmas = <0x20 0x10 0x12 0x00 0x20 0x11 0x12 0x00>;
				dma-names = "rx", "tx";
				status = "okay";
				assigned-clocks = <0x02 0x88>;
				assigned-clock-parents = <0x02 0x1b>;
				assigned-clock-rates = <0x1770000>;
				phandle = <0x71>;
			};

			sai@308b0000 {
				#sound-dai-cells = <0x00>;
				compatible = "fsl,imx8mq-sai";
				reg = <0x308b0000 0x10000>;
				interrupts = <0x00 0x60 0x04>;
				clocks = <0x02 0xef 0x02 0xc5 0x02 0x00 0x02 0x00>;
				clock-names = "bus", "mclk1", "mclk2", "mclk3";
				dmas = <0x20 0x0a 0x18 0x00 0x20 0x0b 0x18 0x00>;
				dma-names = "rx", "tx";
				status = "okay";
				pinctrl-names = "default";
				pinctrl-0 = <0x32>;
				assigned-clocks = <0x02 0x1a 0x02 0x82>;
				assigned-clock-parents = <0x02 0x19 0x02 0x1b>;
				assigned-clock-rates = <0x00 0x1770000>;
				phandle = <0x6e>;
			};

			sai@308c0000 {
				#sound-dai-cells = <0x00>;
				compatible = "fsl,imx8mq-sai";
				reg = <0x308c0000 0x10000>;
				interrupts = <0x00 0x32 0x04>;
				clocks = <0x02 0xf0 0x02 0xc6 0x02 0x00 0x02 0x00>;
				clock-names = "bus", "mclk1", "mclk2", "mclk3";
				dmas = <0x20 0x0c 0x18 0x00 0x20 0x0d 0x18 0x00>;
				dma-names = "rx", "tx";
				status = "okay";
				pinctrl-names = "default";
				pinctrl-0 = <0x33>;
				assigned-clocks = <0x02 0x83>;
				assigned-clock-parents = <0x02 0x1b>;
				assigned-clock-rates = <0x1770000>;
				phandle = <0x6b>;
			};

			crypto@30900000 {
				compatible = "fsl,sec-v4.0";
				#address-cells = <0x01>;
				#size-cells = <0x01>;
				reg = <0x30900000 0x40000>;
				ranges = <0x00 0x30900000 0x40000>;
				interrupts = <0x00 0x5b 0x04>;
				clocks = <0x02 0x74 0x02 0xec>;
				clock-names = "aclk", "ipg";

				jr@1000 {
					compatible = "fsl,sec-v4.0-job-ring";
					reg = <0x1000 0x1000>;
					interrupts = <0x00 0x69 0x04>;
					status = "disabled";
				};

				jr@2000 {
					compatible = "fsl,sec-v4.0-job-ring";
					reg = <0x2000 0x1000>;
					interrupts = <0x00 0x6a 0x04>;
				};

				jr@3000 {
					compatible = "fsl,sec-v4.0-job-ring";
					reg = <0x3000 0x1000>;
					interrupts = <0x00 0x72 0x04>;
				};
			};

			dsi@30a00000 {
				compatible = "fsl,imx8mq-nwl-dsi";
				reg = <0x30a00000 0x300>;
				#address-cells = <0x01>;
				#size-cells = <0x00>;
				clocks = <0x02 0xa3 0x02 0xf4 0x02 0xf5 0x02 0xa4 0x02 0x80>;
				clock-names = "core", "rx_esc", "tx_esc", "phy_ref", "lcdif";
				assigned-clocks = <0x02 0xf4 0x02 0xa3 0x02 0xf5>;
				assigned-clock-parents = <0x02 0x47 0x02 0x4c>;
				assigned-clock-rates = <0x4c4b400 0xfdad680 0x1312d00>;
				interrupts = <0x00 0x22 0x04>;
				mux-controls = <0x34 0x00>;
				power-domains = <0x35>;
				phys = <0x36>;
				phy-names = "dphy";
				resets = <0x37 0x15 0x37 0x17 0x37 0x18 0x37 0x19>;
				reset-names = "byte", "dpi", "esc", "pclk";
				status = "okay";

				ports {
					#address-cells = <0x01>;
					#size-cells = <0x00>;

					port@0 {
						reg = <0x00>;
						#address-cells = <0x01>;
						#size-cells = <0x00>;

						endpoint@0 {
							reg = <0x00>;
							remote-endpoint = <0x38>;
							phandle = <0x24>;
						};
					};

					port@1 {
						reg = <0x01>;

						endpoint {
							remote-endpoint = <0x39>;
							phandle = <0x3c>;
						};
					};
				};

				panel@0 {
					pinctrl-0 = <0x3a>;
					pinctrl-names = "default";
					compatible = "raydium,rm67191";
					reg = <0x00>;
					reset-gpios = <0x3b 0x06 0x01>;
					dsi-lanes = <0x04>;

					port {

						endpoint {
							remote-endpoint = <0x3c>;
							phandle = <0x39>;
						};
					};
				};
			};

			dphy@30a00300 {
				compatible = "fsl,imx8mq-mipi-dphy";
				reg = <0x30a00300 0x100>;
				clocks = <0x02 0xa4>;
				clock-names = "phy_ref";
				assigned-clocks = <0x02 0x21 0x02 0x24 0x02 0xa4 0x02 0x23>;
				assigned-clock-parents = <0x02 0x02 0x02 0x23 0x02 0x25>;
				assigned-clock-rates = <0x00 0x00 0x16e3600 0x2367b880>;
				#phy-cells = <0x00>;
				power-domains = <0x35>;
				status = "okay";
				phandle = <0x36>;
			};

			i2c@30a20000 {
				compatible = "fsl,imx8mq-i2c", "fsl,imx21-i2c";
				reg = <0x30a20000 0x10000>;
				interrupts = <0x00 0x23 0x04>;
				clocks = <0x02 0xb8>;
				#address-cells = <0x01>;
				#size-cells = <0x00>;
				status = "okay";
				clock-frequency = <0x186a0>;
				pinctrl-names = "default";
				pinctrl-0 = <0x3d>;

				pmic@8 {
					compatible = "fsl,pfuze100";
					reg = <0x08>;

					regulators {

						sw1ab {
							regulator-min-microvolt = <0xc96a8>;
							regulator-max-microvolt = <0x10c8e0>;
							phandle = <0x2e>;
						};

						sw1c {
							regulator-min-microvolt = <0xc96a8>;
							regulator-max-microvolt = <0x10c8e0>;
							phandle = <0x2f>;
						};

						sw2 {
							regulator-min-microvolt = <0x10c8e0>;
							regulator-max-microvolt = <0x10c8e0>;
							regulator-always-on;
						};

						sw3ab {
							regulator-min-microvolt = <0xc96a8>;
							regulator-max-microvolt = <0x10c8e0>;
							regulator-always-on;
						};

						sw4 {
							regulator-min-microvolt = <0x1b7740>;
							regulator-max-microvolt = <0x1b7740>;
							regulator-always-on;
							phandle = <0x49>;
						};

						swbst {
							regulator-min-microvolt = <0x4c4b40>;
							regulator-max-microvolt = <0x4e9530>;
						};

						vsnvs {
							regulator-min-microvolt = <0xf4240>;
							regulator-max-microvolt = <0x2dc6c0>;
							regulator-always-on;
						};

						vrefddr {
							regulator-always-on;
						};

						vgen1 {
							regulator-min-microvolt = "", "\f5";
							regulator-max-microvolt = <0x17a6b0>;
						};

						vgen2 {
							regulator-min-microvolt = <0xcf850>;
							regulator-max-microvolt = <0xee098>;
							regulator-always-on;
						};

						vgen3 {
							regulator-min-microvolt = <0x198ef8>;
							regulator-max-microvolt = <0x1e22d8>;
							regulator-always-on;
						};

						vgen4 {
							regulator-min-microvolt = <0x18cba8>;
							regulator-max-microvolt = <0x1c9c38>;
							regulator-always-on;
						};

						vgen5 {
							regulator-min-microvolt = <0x2eebb8>;
							regulator-max-microvolt = <0x375028>;
							regulator-always-on;
							phandle = <0x62>;
						};

						vgen6 {
							regulator-min-microvolt = <0x1b7740>;
							regulator-max-microvolt = <0x325aa0>;
						};
					};
				};
			};

			i2c@30a30000 {
				compatible = "fsl,imx8mq-i2c", "fsl,imx21-i2c";
				reg = <0x30a30000 0x10000>;
				interrupts = <0x00 0x24 0x04>;
				clocks = <0x02 0xb9>;
				#address-cells = <0x01>;
				#size-cells = <0x00>;
				status = "disabled";
			};

			i2c@30a40000 {
				compatible = "fsl,imx8mq-i2c", "fsl,imx21-i2c";
				reg = <0x30a40000 0x10000>;
				interrupts = <0x00 0x25 0x04>;
				clocks = <0x02 0xba>;
				#address-cells = <0x01>;
				#size-cells = <0x00>;
				status = "disabled";
			};

			i2c@30a50000 {
				compatible = "fsl,imx8mq-i2c", "fsl,imx21-i2c";
				reg = <0x30a50000 0x10000>;
				interrupts = <0x00 0x26 0x04>;
				clocks = <0x02 0xbb>;
				#address-cells = <0x01>;
				#size-cells = <0x00>;
				status = "disabled";
			};

			serial@30a60000 {
				compatible = "fsl,imx8mq-uart", "fsl,imx6q-uart";
				reg = <0x30a60000 0x10000>;
				interrupts = <0x00 0x1d 0x04>;
				clocks = <0x02 0xcd 0x02 0xcd>;
				clock-names = "ipg", "per";
				dmas = <0x20 0x1c 0x04 0x00 0x20 0x1d 0x04 0x00>;
				dma-names = "rx", "tx";
				status = "disabled";
			};

			csi@30a70000 {
				compatible = "fsl,imx8mq-mipi-csi2";
				reg = <0x30a70000 0x1000>;
				clocks = <0x02 0xa7 0x02 0xa9 0x02 0xa8>;
				clock-names = "core", "esc", "ui";
				assigned-clocks = <0x02 0xa7 0x02 0xa8 0x02 0xa9>;
				assigned-clock-rates = <0xfdad680 0x13d92d40 0x3ef1480>;
				assigned-clock-parents = <0x02 0x4c 0x02 0x57 0x02 0x4e>;
				power-domains = <0x3e>;
				resets = <0x37 0x26 0x37 0x27 0x37 0x28>;
				fsl,mipi-phy-gpr = <0x3f 0x88>;
				interconnects = <0x40 0x0e 0x40 0x02>;
				interconnect-names = "dram";
				status = "disabled";

				ports {
					#address-cells = <0x01>;
					#size-cells = <0x00>;

					port@1 {
						reg = <0x01>;

						endpoint {
							remote-endpoint = <0x41>;
							phandle = <0x42>;
						};
					};
				};
			};

			csi@30a90000 {
				compatible = "fsl,imx8mq-csi";
				reg = <0x30a90000 0x10000>;
				interrupts = <0x00 0x2a 0x04>;
				clocks = <0x02 0xe0>;
				clock-names = "mclk";
				status = "disabled";

				port {

					endpoint {
						remote-endpoint = <0x42>;
						phandle = <0x41>;
					};
				};
			};

			csi@30b60000 {
				compatible = "fsl,imx8mq-mipi-csi2";
				reg = <0x30b60000 0x1000>;
				clocks = <0x02 0xaa 0x02 0xac 0x02 0xab>;
				clock-names = "core", "esc", "ui";
				assigned-clocks = <0x02 0xaa 0x02 0xab 0x02 0xac>;
				assigned-clock-rates = <0xfdad680 0x13d92d40 0x3ef1480>;
				assigned-clock-parents = <0x02 0x4c 0x02 0x57 0x02 0x4e>;
				power-domains = <0x43>;
				resets = <0x37 0x29 0x37 0x2a 0x37 0x2b>;
				fsl,mipi-phy-gpr = <0x3f 0xa4>;
				interconnects = <0x40 0x0f 0x40 0x02>;
				interconnect-names = "dram";
				status = "disabled";

				ports {
					#address-cells = <0x01>;
					#size-cells = <0x00>;

					port@1 {
						reg = <0x01>;

						endpoint {
							remote-endpoint = <0x44>;
							phandle = <0x45>;
						};
					};
				};
			};

			csi@30b80000 {
				compatible = "fsl,imx8mq-csi";
				reg = <0x30b80000 0x10000>;
				interrupts = <0x00 0x2b 0x04>;
				clocks = <0x02 0xe1>;
				clock-names = "mclk";
				status = "disabled";

				port {

					endpoint {
						remote-endpoint = <0x45>;
						phandle = <0x44>;
					};
				};
			};

			mailbox@30aa0000 {
				compatible = "fsl,imx8mq-mu", "fsl,imx6sx-mu";
				reg = <0x30aa0000 0x10000>;
				interrupts = <0x00 0x58 0x04>;
				clocks = <0x02 0xfd>;
				#mbox-cells = <0x02>;
			};

			mmc@30b40000 {
				compatible = "fsl,imx8mq-usdhc", "fsl,imx7d-usdhc";
				reg = <0x30b40000 0x10000>;
				interrupts = <0x00 0x16 0x04>;
				clocks = <0x02 0xec 0x02 0x69 0x02 0xd2>;
				clock-names = "ipg", "ahb", "per";
				fsl,tuning-start-tap = <0x14>;
				fsl,tuning-step = <0x02>;
				bus-width = <0x08>;
				status = "okay";
				assigned-clocks = <0x02 0x8e>;
				assigned-clock-rates = <0x17d78400>;
				pinctrl-names = "default", "state_100mhz", "state_200mhz";
				pinctrl-0 = <0x46>;
				pinctrl-1 = <0x47>;
				pinctrl-2 = <0x48>;
				vqmmc-supply = <0x49>;
				non-removable;
				no-sd;
				no-sdio;
			};

			mmc@30b50000 {
				compatible = "fsl,imx8mq-usdhc", "fsl,imx7d-usdhc";
				reg = <0x30b50000 0x10000>;
				interrupts = <0x00 0x17 0x04>;
				clocks = <0x02 0xec 0x02 0x69 0x02 0xd3>;
				clock-names = "ipg", "ahb", "per";
				fsl,tuning-start-tap = <0x14>;
				fsl,tuning-step = <0x02>;
				bus-width = <0x04>;
				status = "okay";
				assigned-clocks = <0x02 0x8f>;
				assigned-clock-rates = <0xbebc200>;
				pinctrl-names = "default", "state_100mhz", "state_200mhz";
				pinctrl-0 = <0x4a 0x4b>;
				pinctrl-1 = <0x4c 0x4b>;
				pinctrl-2 = <0x4d 0x4b>;
				cd-gpios = <0x4e 0x0c 0x01>;
				vmmc-supply = <0x4f>;
			};

			spi@30bb0000 {
				#address-cells = <0x01>;
				#size-cells = <0x00>;
				compatible = "fsl,imx8mq-qspi", "fsl,imx7d-qspi";
				reg = <0x30bb0000 0x10000 0x8000000 0x10000000>;
				reg-names = "QuadSPI", "QuadSPI-memory";
				interrupts = <0x00 0x6b 0x04>;
				clocks = <0x02 0xc3 0x02 0xc3>;
				clock-names = "qspi_en", "qspi";
				status = "okay";
				pinctrl-names = "default";
				pinctrl-0 = <0x50>;

				flash@0 {
					reg = <0x00>;
					#address-cells = <0x01>;
					#size-cells = <0x01>;
					compatible = "micron,n25q256a", "jedec,spi-nor";
					spi-max-frequency = <0x1ba8140>;
					spi-tx-bus-width = <0x01>;
					spi-rx-bus-width = <0x04>;
				};
			};

			dma-controller@30bd0000 {
				compatible = "fsl,imx8mq-sdma", "fsl,imx7d-sdma";
				reg = <0x30bd0000 0x10000>;
				interrupts = <0x00 0x02 0x04>;
				clocks = <0x02 0xe3 0x02 0x74>;
				clock-names = "ipg", "ahb";
				#dma-cells = <0x03>;
				fsl,sdma-ram-script-name = "imx/sdma/sdma-imx7d.bin";
				phandle = <0x20>;
			};

			ethernet@30be0000 {
				compatible = "fsl,imx8mq-fec", "fsl,imx6sx-fec";
				reg = <0x30be0000 0x10000>;
				interrupts = <0x00 0x76 0x04 0x00 0x77 0x04 0x00 0x78 0x04 0x00 0x79 0x04>;
				clocks = <0x02 0xb6 0x02 0xb6 0x02 0x8a 0x02 0x89 0x02 0x8b>;
				clock-names = "ipg", "ahb", "ptp", "enet_clk_ref", "enet_out";
				assigned-clocks = <0x02 0x68 0x02 0x8a 0x02 0x89 0x02 0x8b>;
				assigned-clock-parents = <0x02 0x4c 0x02 0x50 0x02 0x51 0x02 0x4f>;
				assigned-clock-rates = <0x00 0x5f5e100 0x7735940 0x00>;
				fsl,num-tx-queues = <0x03>;
				fsl,num-rx-queues = <0x03>;
				nvmem-cells = <0x51>;
				nvmem-cell-names = "mac-address";
				fsl,stop-mode = <0x3f 0x10 0x03>;
				status = "okay";
				pinctrl-names = "default";
				pinctrl-0 = <0x52>;
				phy-mode = "rgmii-id";
				phy-handle = <0x53>;
				fsl,magic-packet;

				mdio {
					#address-cells = <0x01>;
					#size-cells = <0x00>;

					ethernet-phy@0 {
						compatible = "ethernet-phy-ieee802.3-c22";
						reg = <0x00>;
						reset-gpios = <0x54 0x09 0x01>;
						reset-assert-us = <0x2710>;
						qca,disable-smarteee;
						vddio-supply = <0x55>;
						phandle = <0x53>;

						vddh-regulator {
							phandle = <0x55>;
						};
					};
				};
			};
		};

		interconnect@32700000 {
			compatible = "fsl,imx8mq-noc", "fsl,imx8m-noc";
			reg = <0x32700000 0x100000>;
			clocks = <0x02 0x71>;
			fsl,ddrc = <0x56>;
			#interconnect-cells = <0x01>;
			operating-points-v2 = <0x57>;
			phandle = <0x40>;

			opp-table {
				compatible = "operating-points-v2";
				phandle = <0x57>;

				opp-133000000 {
					opp-hz = <0x00 0x7f28155>;
				};

				opp-400000000 {
					opp-hz = <0x00 0x17d78400>;
				};

				opp-800000000 {
					opp-hz = <0x00 0x2faf0800>;
				};
			};
		};

		bus@32c00000 {
			compatible = "fsl,aips-bus", "simple-bus";
			reg = <0x32c00000 0x400000>;
			#address-cells = <0x01>;
			#size-cells = <0x01>;
			ranges = <0x32c00000 0x32c00000 0x400000>;

			interrupt-controller@32e2d000 {
				compatible = "fsl,imx8m-irqsteer", "fsl,imx-irqsteer";
				reg = <0x32e2d000 0x1000>;
				interrupts = <0x00 0x12 0x04>;
				clocks = <0x02 0xf8>;
				clock-names = "ipg";
				fsl,channel = <0x00>;
				fsl,num-irqs = <0x40>;
				interrupt-controller;
				#interrupt-cells = <0x01>;
			};
		};

		gpu@38000000 {
			compatible = "vivante,gc";
			reg = <0x38000000 0x40000>;
			interrupts = <0x00 0x03 0x04>;
			clocks = <0x02 0xd7 0x02 0x66 0x02 0x6f 0x02 0x70>;
			clock-names = "core", "shader", "bus", "reg";
			#cooling-cells = <0x02>;
			assigned-clocks = <0x02 0x61 0x02 0x64 0x02 0x6f 0x02 0x70 0x02 0x10>;
			assigned-clock-parents = <0x02 0x11 0x02 0x11 0x02 0x11 0x02 0x11 0x02 0x0f>;
			assigned-clock-rates = <0x2faf0800 0x2faf0800 0x2faf0800 0x2faf0800 0x00>;
			power-domains = <0x58>;
			phandle = <0x14>;
		};

		usb@38100000 {
			compatible = "fsl,imx8mq-dwc3", "snps,dwc3";
			reg = <0x38100000 0x10000>;
			clocks = <0x02 0xce 0x02 0x98 0x02 0x01>;
			clock-names = "bus_early", "ref", "suspend";
			assigned-clocks = <0x02 0x6e 0x02 0x98>;
			assigned-clock-parents = <0x02 0x56 0x02 0x48>;
			assigned-clock-rates = <0x1dcd6500 0x5f5e100>;
			interrupts = <0x00 0x28 0x04>;
			phys = <0x59 0x59>;
			phy-names = "usb2-phy", "usb3-phy";
			power-domains = <0x5a>;
			snps,parkmode-disable-ss-quirk;
			status = "disabled";
		};

		usb-phy@381f0040 {
			compatible = "fsl,imx8mq-usb-phy";
			reg = <0x381f0040 0x40>;
			clocks = <0x02 0xd0>;
			clock-names = "phy";
			assigned-clocks = <0x02 0x99>;
			assigned-clock-parents = <0x02 0x48>;
			assigned-clock-rates = <0x5f5e100>;
			#phy-cells = <0x00>;
			status = "disabled";
			phandle = <0x59>;
		};

		usb@38200000 {
			compatible = "fsl,imx8mq-dwc3", "snps,dwc3";
			reg = <0x38200000 0x10000>;
			clocks = <0x02 0xcf 0x02 0x98 0x02 0x01>;
			clock-names = "bus_early", "ref", "suspend";
			assigned-clocks = <0x02 0x6e 0x02 0x98>;
			assigned-clock-parents = <0x02 0x56 0x02 0x48>;
			assigned-clock-rates = <0x1dcd6500 0x5f5e100>;
			interrupts = <0x00 0x29 0x04>;
			phys = <0x5b 0x5b>;
			phy-names = "usb2-phy", "usb3-phy";
			power-domains = <0x5c>;
			snps,parkmode-disable-ss-quirk;
			status = "okay";
			dr_mode = "host";
		};

		usb-phy@382f0040 {
			compatible = "fsl,imx8mq-usb-phy";
			reg = <0x382f0040 0x40>;
			clocks = <0x02 0xd1>;
			clock-names = "phy";
			assigned-clocks = <0x02 0x99>;
			assigned-clock-parents = <0x02 0x48>;
			assigned-clock-rates = <0x5f5e100>;
			#phy-cells = <0x00>;
			status = "okay";
			phandle = <0x5b>;
		};

		video-codec@38300000 {
			compatible = "nxp,imx8mq-vpu-g1";
			reg = <0x38300000 0x10000>;
			interrupts = <0x00 0x07 0x04>;
			clocks = <0x02 0xe5>;
			power-domains = <0x5d 0x00>;
		};

		video-codec@38310000 {
			compatible = "nxp,imx8mq-vpu-g2";
			reg = <0x38310000 0x10000>;
			interrupts = <0x00 0x08 0x04>;
			clocks = <0x02 0xe6>;
			power-domains = <0x5d 0x01>;
		};

		blk-ctrl@38320000 {
			compatible = "fsl,imx8mq-vpu-blk-ctrl";
			reg = <0x38320000 0x100>;
			power-domains = <0x5e 0x5e 0x5e>;
			power-domain-names = "bus", "g1", "g2";
			clocks = <0x02 0xe5 0x02 0xe6>;
			clock-names = "g1", "g2";
			#power-domain-cells = <0x01>;
			phandle = <0x5d>;
		};

		pcie@33800000 {
			compatible = "fsl,imx8mq-pcie";
			reg = <0x33800000 0x400000 0x1ff00000 0x80000>;
			reg-names = "dbi", "config";
			#address-cells = <0x03>;
			#size-cells = <0x02>;
			device_type = "pci";
			bus-range = <0x00 0xff>;
			ranges = <0x81000000 0x00 0x00 0x1ff80000 0x00 0x10000 0x82000000 0x00 0x18000000 0x18000000 0x00 0x7f00000>;
			num-lanes = <0x01>;
			interrupts = <0x00 0x7a 0x04>;
			interrupt-names = "msi";
			#interrupt-cells = <0x01>;
			interrupt-map-mask = <0x00 0x00 0x00 0x07>;
			interrupt-map = <0x00 0x00 0x00 0x01 0x0c 0x00 0x7d 0x04 0x00 0x00 0x00 0x02 0x0c 0x00 0x7c 0x04 0x00 0x00 0x00 0x03 0x0c 0x00 0x7b 0x04 0x00 0x00 0x00 0x04 0x0c 0x00 0x7a 0x04>;
			fsl,max-link-speed = <0x02>;
			linux,pci-domain = <0x00>;
			clocks = <0x02 0xbd 0x5f 0x02 0x7d 0x02 0x7e>;
			clock-names = "pcie", "pcie_bus", "pcie_phy", "pcie_aux";
			power-domains = <0x60>;
			resets = <0x37 0x1a 0x37 0x1c 0x37 0x1d>;
			reset-names = "pciephy", "apps", "turnoff";
			assigned-clocks = <0x02 0x7c 0x02 0x7d 0x02 0x7e>;
			assigned-clock-parents = <0x02 0x54 0x02 0x50 0x02 0x47>;
			assigned-clock-rates = <0xee6b280 0x5f5e100 0x989680>;
			status = "okay";
			pinctrl-names = "default";
			pinctrl-0 = <0x61>;
			reset-gpio = <0x3b 0x1c 0x01>;
			vph-supply = <0x62>;
		};

		pcie@33c00000 {
			compatible = "fsl,imx8mq-pcie";
			reg = <0x33c00000 0x400000 0x27f00000 0x80000>;
			reg-names = "dbi", "config";
			#address-cells = <0x03>;
			#size-cells = <0x02>;
			device_type = "pci";
			bus-range = <0x00 0xff>;
			ranges = <0x81000000 0x00 0x00 0x27f80000 0x00 0x10000 0x82000000 0x00 0x20000000 0x20000000 0x00 0x7f00000>;
			num-lanes = <0x01>;
			interrupts = <0x00 0x4a 0x04>;
			interrupt-names = "msi";
			#interrupt-cells = <0x01>;
			interrupt-map-mask = <0x00 0x00 0x00 0x07>;
			interrupt-map = <0x00 0x00 0x00 0x01 0x0c 0x00 0x4d 0x04 0x00 0x00 0x00 0x02 0x0c 0x00 0x4c 0x04 0x00 0x00 0x00 0x03 0x0c 0x00 0x4b 0x04 0x00 0x00 0x00 0x04 0x0c 0x00 0x4a 0x04>;
			fsl,max-link-speed = <0x02>;
			linux,pci-domain = <0x01>;
			clocks = <0x02 0xbe 0x5f 0x02 0xae 0x02 0xaf>;
			clock-names = "pcie", "pcie_bus", "pcie_phy", "pcie_aux";
			power-domains = <0x60>;
			resets = <0x37 0x22 0x37 0x24 0x37 0x25>;
			reset-names = "pciephy", "apps", "turnoff";
			assigned-clocks = <0x02 0xad 0x02 0xae 0x02 0xaf>;
			assigned-clock-parents = <0x02 0x54 0x02 0x50 0x02 0x47>;
			assigned-clock-rates = <0xee6b280 0x5f5e100 0x989680>;
			status = "okay";
			pinctrl-names = "default";
			pinctrl-0 = <0x63>;
			reset-gpio = <0x3b 0x0c 0x01>;
			vpcie-supply = <0x64>;
			vph-supply = <0x62>;
		};

		pcie-ep@33c00000 {
			compatible = "fsl,imx8mq-pcie-ep";
			reg = <0x33c00000 0x400000 0x20000000 0x8000000>;
			reg-names = "dbi", "addr_space";
			num-lanes = <0x01>;
			interrupts = <0x00 0x50 0x04>;
			interrupt-names = "dma";
			fsl,max-link-speed = <0x02>;
			clocks = <0x02 0xbe 0x02 0xae 0x02 0xae 0x02 0xaf>;
			clock-names = "pcie", "pcie_bus", "pcie_phy", "pcie_aux";
			power-domains = <0x60>;
			resets = <0x37 0x22 0x37 0x24 0x37 0x25>;
			reset-names = "pciephy", "apps", "turnoff";
			assigned-clocks = <0x02 0xad 0x02 0xae 0x02 0xaf>;
			assigned-clock-parents = <0x02 0x54 0x02 0x50 0x02 0x47>;
			assigned-clock-rates = <0xee6b280 0x5f5e100 0x989680>;
			num-ib-windows = <0x04>;
			num-ob-windows = <0x04>;
			status = "disabled";
		};

		interrupt-controller@38800000 {
			compatible = "arm,gic-v3";
			reg = <0x38800000 0x10000 0x38880000 0xc0000 0x31000000 0x2000 0x31010000 0x2000 0x31020000 0x2000>;
			#interrupt-cells = <0x03>;
			interrupt-controller;
			interrupts = <0x01 0x09 0x04>;
			interrupt-parent = <0x0c>;
			phandle = <0x0c>;
		};

		memory-controller@3d400000 {
			compatible = "fsl,imx8mq-ddrc", "fsl,imx8m-ddrc";
			reg = <0x3d400000 0x400000>;
			clock-names = "core", "pll", "alt", "apb";
			clocks = <0x02 0xfc 0x02 0xea 0x02 0x76 0x02 0x77>;
			status = "okay";
			operating-points-v2 = <0x65>;
			phandle = <0x56>;

			opp-table {
				compatible = "operating-points-v2";
				phandle = <0x65>;

				opp-25000000 {
					opp-hz = <0x00 0x17d7840>;
				};

				opp-100000000 {
					opp-hz = <0x00 0x5f5e100>;
				};

				opp-166000000 {
					opp-hz = <0x00 0x9f33bbb>;
				};

				opp-800000000 {
					opp-hz = <0x00 0x2faf0800>;
				};
			};
		};

		ddr-pmu@3d800000 {
			compatible = "fsl,imx8mq-ddr-pmu", "fsl,imx8m-ddr-pmu";
			reg = <0x3d800000 0x400000>;
			interrupt-parent = <0x0c>;
			interrupts = <0x00 0x62 0x04>;
		};
	};

	chosen {
		stdout-path = "/soc@0/bus@30800000/serial@30860000";
	};

	memory@40000000 {
		device_type = "memory";
		reg = <0x00 0x40000000 0x00 0xc0000000>;
	};

	pcie0-refclk {
		compatible = "fixed-clock";
		#clock-cells = <0x00>;
		clock-frequency = <0x5f5e100>;
		phandle = <0x5f>;
	};

	regulator-pcie {
		compatible = "regulator-fixed";
		pinctrl-names = "default";
		pinctrl-0 = <0x66>;
		regulator-name = "MPCIE_3V3";
		regulator-min-microvolt = <0x325aa0>;
		regulator-max-microvolt = <0x325aa0>;
		gpio = <0x3b 0x0a 0x00>;
		enable-active-high;
		phandle = <0x64>;
	};

	regulator-vsd-3v3 {
		pinctrl-names = "default";
		pinctrl-0 = <0x67>;
		compatible = "regulator-fixed";
		regulator-name = "VSD_3V3";
		regulator-min-microvolt = <0x325aa0>;
		regulator-max-microvolt = <0x325aa0>;
		gpio = <0x4e 0x13 0x00>;
		off-on-delay-us = <0x4e20>;
		enable-active-high;
		phandle = <0x4f>;
	};

	regulator-buck2 {
		pinctrl-names = "default";
		pinctrl-0 = <0x68>;
		compatible = "regulator-gpio";
		regulator-name = "vdd_arm";
		regulator-min-microvolt = <0xdbba0>;
		regulator-max-microvolt = <0xf4240>;
		gpios = <0x54 0x0d 0x00>;
		states = <0xf4240 0x00 0xdbba0 0x01>;
		regulator-boot-on;
		regulator-always-on;
		phandle = <0x06>;
	};

	ir-receiver {
		compatible = "gpio-ir-receiver";
		gpios = <0x54 0x0c 0x01>;
		pinctrl-names = "default";
		pinctrl-0 = <0x69>;
		linux,autosuspend-period = <0x7d>;
	};

	audio-codec-bt-sco {
		compatible = "linux,bt-sco";
		#sound-dai-cells = <0x01>;
		phandle = <0x6c>;
	};

	audio-codec {
		#sound-dai-cells = <0x00>;
		compatible = "wlf,wm8524";
		wlf,mute-gpios = <0x54 0x08 0x01>;
		phandle = <0x6f>;
	};

	sound-bt-sco {
		compatible = "simple-audio-card";
		simple-audio-card,name = "bt-sco-audio";
		simple-audio-card,format = "dsp_a";
		simple-audio-card,bitclock-inversion;
		simple-audio-card,frame-master = <0x6a>;
		simple-audio-card,bitclock-master = <0x6a>;

		simple-audio-card,cpu {
			sound-dai = <0x6b>;
			dai-tdm-slot-num = <0x02>;
			dai-tdm-slot-width = <0x10>;
			phandle = <0x6a>;
		};

		simple-audio-card,codec {
			sound-dai = <0x6c 0x01>;
		};
	};

	sound-wm8524 {
		compatible = "simple-audio-card";
		simple-audio-card,name = "wm8524-audio";
		simple-audio-card,format = "i2s";
		simple-audio-card,frame-master = <0x6d>;
		simple-audio-card,bitclock-master = <0x6d>;
		simple-audio-card,widgets = "Line", "Left Line Out Jack", "Line", "Right Line Out Jack";
		simple-audio-card,routing = "Left Line Out Jack", "LINEVOUTL", "Right Line Out Jack", "LINEVOUTR";

		simple-audio-card,cpu {
			sound-dai = <0x6e>;
			phandle = <0x6d>;
		};

		simple-audio-card,codec {
			sound-dai = <0x6f>;
			clocks = <0x02 0xc5>;
		};
	};

	sound-spdif {
		compatible = "fsl,imx-audio-spdif";
		model = "imx-spdif";
		spdif-controller = <0x70>;
		spdif-out;
		spdif-in;
	};

	sound-hdmi-arc {
		compatible = "fsl,imx-audio-spdif";
		model = "imx-hdmi-arc";
		spdif-controller = <0x71>;
		spdif-in;
	};
};
